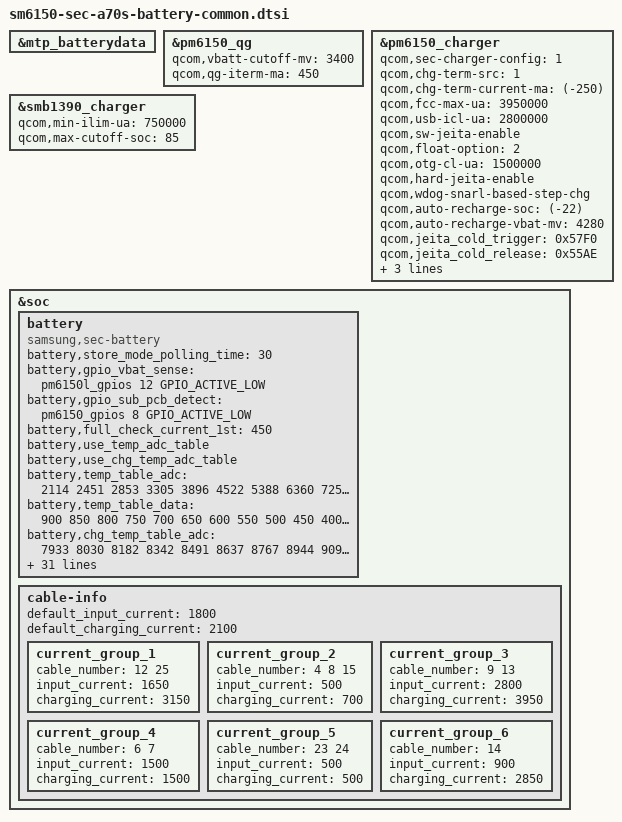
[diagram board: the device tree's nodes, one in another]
/* Copyright (c) 2014, The Linux Foundation. All rights reserved.
 *
 * This program is free software; you can redistribute it and/or modify
 * it under the terms of the GNU General Public License version 2 and
 * only version 2 as published by the Free Software Foundation.
 *
 * This program is distributed in the hope that it will be useful,
 * but WITHOUT ANY WARRANTY; without even the implied warranty of
 * MERCHANTABILITY or FITNESS FOR A PARTICULAR PURPOSE.  See the
 * GNU General Public License for more details.
 */

&mtp_batterydata {
	/delete-node/ qcom,alium_860_89032_0000_3600mAh;
	/delete-node/ qcom,mlp356477_2800mah;
	#include "sm6150-sec-qg-batterydata-a70q.dtsi"
};

&pm6150_qg {
	qcom,vbatt-cutoff-mv = <3400>;	/* SOC 0% */
	qcom,qg-iterm-ma = <450>;		/* SOC 100% */
};

&pm6150_charger {
	/delete-property/ qcom,sec-charger-config;
	qcom,sec-charger-config = <1>;
	qcom,chg-term-src = <1>;	/* 0 : 	ITERM_SRC_UNSPECIFIED, 1 : ITERM_SRC_ADC, 2 : ITERM_SRC_ANALOG */
	qcom,chg-term-current-ma = <(-250)>;
	qcom,fcc-max-ua = <3950000>;
	qcom,usb-icl-ua = <2800000>;
	qcom,sw-jeita-enable;
	qcom,float-option = <2>;
	qcom,otg-cl-ua = <1500000>;
	qcom,hard-jeita-enable;
	qcom,wdog-snarl-based-step-chg;
	qcom,auto-recharge-soc = <(-22)>;
	qcom,auto-recharge-vbat-mv = <4280>;

	qcom,jeita_cold_trigger = <0x57F0>;		/* 0 degree */
	qcom,jeita_cold_release = <0x55AE>;		/* 2 degree */
	qcom,jeita_hot_trigger = <0x1C52>;		/* 50 degree */
	qcom,jeita_hot_release = <0x1E14>;		/* 48 degree */

	rid-gnd-gpio = <&pm6150l_gpios 9 GPIO_ACTIVE_LOW>;
};

&smb1390_charger {
	qcom,min-ilim-ua = <750000>;
	qcom,max-cutoff-soc = <85>;
};

&soc {
	battery {
		status = "okay";
		compatible = "samsung,sec-battery";
		battery,store_mode_polling_time = <30>;
		battery,gpio_vbat_sense = <&pm6150l_gpios 12 GPIO_ACTIVE_LOW>;
		battery,gpio_sub_pcb_detect = <&pm6150_gpios 8 GPIO_ACTIVE_LOW>;
		battery,full_check_current_1st = <450>;
		battery,use_temp_adc_table;
		battery,use_chg_temp_adc_table;

		battery,temp_table_adc = <2114 2451 2853 3305 3896
						4522 5388 6360 7250 8376
						9721 11193 12793 14423 16240
						17893 19736 21066 22512 23710
						24874 25779 26214>;
		battery,temp_table_data = <900 850 800 750 700
						650 600 550 500 450
						400 350 300 250 200
						150 100 50 0 (-50)
						(-100) (-150) (-200)>;

		battery,chg_temp_table_adc = <7933 8030 8182 8342 8491
						8637 8767 8944 9097 9278
						9431 9589 9752 9915 10071
						10204 10387 10568 10710 10882
						11040 11210 11374>;
		battery,chg_temp_table_data = <(-200) (-150) (-100) (-50) 0
						50 100 150 200 250
						300 350 400 450 500
						550 600 650 700 750
						800 850 900>;

		/* mix temp setting value */
		battery,mix_temp_recovery = <390>;
		battery,mix_temp_batt_threshold = <420>;
		battery,mix_temp_die_threshold = <700>;

		/* chg temp setting value */
		battery,chg_high_temp = <540>;
		battery,chg_high_temp_recovery = <520>;
		battery,chg_input_limit_current = <1000>;
		battery,chg_charging_limit_current = <1250>;

		/* d/c chg temp setting value */
		battery,check_dc_chg_lmit;
		battery,dc_chg_high_temp = <560>;
		battery,dc_chg_high_temp_recovery = <540>;
		battery,dc_chg_input_limit_current = <1200>;
		
		/* Safety timer parameters */
		battery,standard_curr = <3150000>;		//equal to last step of step_chg_ranges
		battery,expired_time = <10920>;		//182min (requested by HQE euna87.kim)
		battery,recharging_expired_time = <5400>;	//90mins
		battery,safety_timer_polling_time = <30>;

		battery,battery_full_capacity = <4400>; /* battery capacity */
		/* disable Vbat ovp dettection */
		battery,cisd_max_voltage_thr = <5000>; /* batttery ovp dettection voltage */
		battery,cisd_alg_index = <7>;

		battery,siop_input_limit_current = <1200>;
		battery,siop_charging_limit_current = <1800>;
		battery,siop_hv_input_limit_current = <700>;
		battery,siop_hv_charging_limit_current = <1800>;
		battery,siop_dc_input_limit_current = <1000>;
		battery,siop_dc_charging_limit_current = <2000>;

		battery,ttf_hv_charge_current = <2550>;
		battery,ttf_dc25_charge_current = <3140>;

		battery,ttf_capacity = <3850>;
		battery,cv_data = <
					1700	840	2340
					1620	847	2280
					1576	854	2220
					1204	861	2160
					1291	868	2100
					1465	874	2040
					1524	881	1980
					1454	886	1920
					1398	892	1860
					1336	898	1800
					1278	903	1740
					1226	908	1680
					1172	913	1620
					1100	918	1560
					1071	923	1500
					1033	927	1440
					987		931	1380
					945		936	1320
					912		940	1260
					872		943	1200
					836		947	1140
					807		951	1080
					769		954	1020
					743		957	960
					719		960	900
					684		963	840
					661		966	780
					633		969	720
					611		971	660
					590		974	600
					566		977	540
					552		979	480
					527		981	420
					512		984	360
					492		986	300
					473		988	240
					458		990	180
					441		992	120
					437		994	60
					435		1000	0
					>;
	};

/* sec_battery_cable
 *   0	UNKNOWN,
 *   1	BATTERY,
 *   2	UPS,
 *   3	MAINS,
 *   4	USB,
 *   5	USB_DCP,
 *   6	USB_CDP,
 *   7	USB_ACA,
 *   8	USB_TYPE_C,
 *   9	USB_PD,
 *  10	USB_PD_DRP,
 *  11	APPLE_BRICK_ID,
 *  12	USB_HVDCP,
 *  13	USB_HVDCP_3,
 *  14	WIRELESS,
 *  15	USB_FLOAT,
 *  16	BMS,
 *  17	PARALLEL,
 *  18	MAIN,
 *  19	WIPOWER,
 *  20	UFP,
 *  21	DFP,
 *  22	CHARGE_PUMP,
 *  23	POWER_SHARING,
 *  24	OTG,
 *  25	AFC,
 *  26	CABLE_MAX,
*/
	cable-info {
		default_input_current = <1800>;
		default_charging_current = <2100>;

		current_group_1 {
			cable_number = <12 25>;
			input_current = <1650>;
			charging_current = <3150>;
		};
		current_group_2 {
			cable_number = <4 8 15>;
			input_current = <500>;
			charging_current = <700>;
		};
		current_group_3 {
			cable_number = <9 13>;
			input_current = <2800>;
			charging_current = <3950>;
		};
		current_group_4 {
			cable_number = <6 7>;
			input_current = <1500>;
			charging_current = <1500>;
		};
		current_group_5 {
			cable_number = <23 24>;
			input_current = <500>;
			charging_current = <500>;
		};
		current_group_6 {
			cable_number = <14>;
			input_current = <900>;
			charging_current = <2850>;
		};
	};
};
